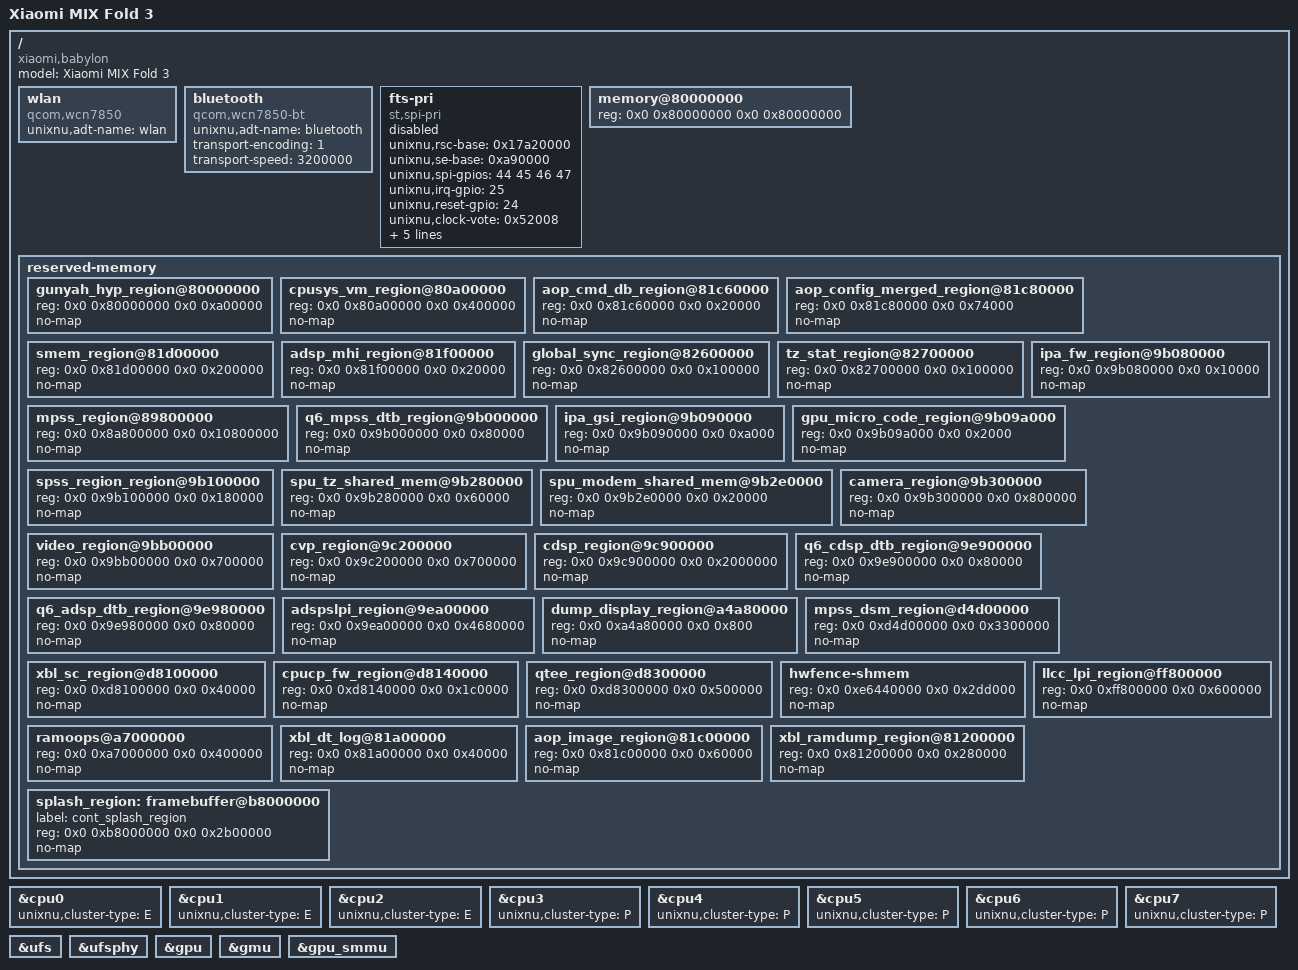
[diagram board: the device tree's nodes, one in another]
/dts-v1/;
/include/ "sm8550.dtsi"

// Generated from babylon live /sys/firmware/fdt (HyperOS 3.0.304.0, Android 16).
// Layout follows UniXNU-sheng dts/sheng.dts; reserved-memory follows UniXNU-zizhan gen_reserved.py approach.

/ {
    model = "Xiaomi MIX Fold 3";
    compatible = "xiaomi,babylon", "qcom,sm8550";

    wlan {
        compatible = "qcom,wcn7850";
        unixnu,adt-name = "wlan";
        status = "okay";
    };

    bluetooth {
        device_type = "bluetooth";
        compatible = "qcom,wcn7850-bt";
        unixnu,adt-name = "bluetooth";
        transport-encoding = <1>;
        transport-speed = <3200000>;
        status = "okay";
    };

    /* ST FingerTip FST2 (st,spi-pri of the stock dtbo fragment@36) on QUP1 SE4.
     *
     * The node is a REQUEST MARKER, not an export. It is deliberately status = "disabled":
     * devicetree.py exports a hardware node only when it carries unixnu,adt-name AND enabled(),
     * and arm_io_window() would then fold reg=0xa90000 into the arm-io base. That base must be
     * 16 MiB aligned and non-zero, so an SE below it would either fail the build ("an exported
     * register lies below 16 MiB") or move the SoC base the kernel reads. Nothing here is
     * exported, so the ADT is byte-for-byte what it was.
     *
     * pong_fts.c is NOT used: it is not in this repository and needs sys/pong_input.h and
     * pong_touch_post(), which exist only in zizhan's Pong input stack. The driver is the FTS
     * stage 1-3 path in package/TouchProbe.cpp, driven by its own FTS_* constants in
     * package/TouchBoard.h (TouchBoard.h is a header, not hardware, so it does not need this
     * node). Every register, pin, clock and rail value is written there, past devicetree.py's
     * hardware_properties() whitelist.
     *
     * Values below are the stock dtbo/baseline-DTB facts, kept with the node as the record. */
    fts-pri {
        compatible = "st,spi-pri";
        status = "disabled";
        /* apps_rsc@17a00000 drv@2 base (the drv-2 reg entry is 0x17a20000), where
         * AudioProbe::micRail() already sends its LDO votes. */
        unixnu,rsc-base = <0x17a20000>;
        /* vboot baseline DTB: /soc/qcom,qupv3_1_geni_se@ac0000/spi@a90000 reg 0xa90000 size 0x4000 */
        unixnu,se-base = <0xa90000>;
        /* qupv3_se4_spi_miso/mosi/clk/cs_active: gpio44/45/46 -> qup1_se4_l0/l1/l2, cs gpio47 */
        unixnu,spi-gpios = <44 45 46 47>;
        unixnu,irq-gpio = <25>;
        unixnu,reset-gpio = <24>;
        unixnu,clock-vote = <0x52008>;
        unixnu,clock-rcg = <0x184f0>;
        /* dvdd-supply -> L12B (pm_humu_l12, 1.8 V), avdd-supply -> L16B (pm_humu_l16, 2.8 V).
         * 2.8 V is the regulator's max: 3.3 V would be out of range. */
        unixnu,supply = "ldob12", "ldob16";
        unixnu,voltage-uv = <1800000 2800000>;
        unixnu,spi-hz = <4000000>;
        unixnu,chip-id = <0x3652>;
    };

    memory@80000000 {
        device_type = "memory";
        /* The low bank the ADT describes. This pair is not what bounds the loader's exclusion
         * walk: DarwinBoot reads darwinboot-memory-size (payload.adt owned_memory_size) for the
         * window and scans the UEFI map inside it, never dram-size. So enlarging this value
         * cannot make DarwinWindowExclusions find ranges, and the sibling window.holes are
         * carried by darwinboot-memory-excluded alone. Keep it equal to board.toml dram_size:
         * devicetree.py refuses the build when the two differ.
         *
         * Writing a size that does not fit one cell is a trap: the root node is
         * #size-cells = <2>, so a range is four cells, and 0x400000000 written as a single
         * cell is truncated by dtc to 0x0. The DTS then declares zero-length DRAM while
         * board.toml still says 16 GiB, and the build dies in packaging on
         * "payload.dram_size differs from the hardware DTS". */
        reg = <0x0 0x80000000 0x0 0x80000000>;
    };

    reserved-memory {
        #address-cells = <2>;
        #size-cells = <2>;
        ranges;
        gunyah_hyp_region@80000000 {
            reg = <0x0 0x80000000 0x0 0xa00000>;
            no-map;
        };
        cpusys_vm_region@80a00000 {
            reg = <0x0 0x80a00000 0x0 0x400000>;
            no-map;
        };
        aop_cmd_db_region@81c60000 {
            reg = <0x0 0x81c60000 0x0 0x20000>;
            no-map;
        };
        aop_config_merged_region@81c80000 {
            reg = <0x0 0x81c80000 0x0 0x74000>;
            no-map;
        };
        smem_region@81d00000 {
            reg = <0x0 0x81d00000 0x0 0x200000>;
            no-map;
        };
        adsp_mhi_region@81f00000 {
            reg = <0x0 0x81f00000 0x0 0x20000>;
            no-map;
        };
        global_sync_region@82600000 {
            reg = <0x0 0x82600000 0x0 0x100000>;
            no-map;
        };
        tz_stat_region@82700000 {
            reg = <0x0 0x82700000 0x0 0x100000>;
            no-map;
        };
        mpss_region@89800000 {
            reg = <0x0 0x8a800000 0x0 0x10800000>;
            no-map;
        };
        q6_mpss_dtb_region@9b000000 {
            reg = <0x0 0x9b000000 0x0 0x80000>;
            no-map;
        };
        ipa_fw_region@9b080000 {
            reg = <0x0 0x9b080000 0x0 0x10000>;
            no-map;
        };
        ipa_gsi_region@9b090000 {
            reg = <0x0 0x9b090000 0x0 0xa000>;
            no-map;
        };
        gpu_micro_code_region@9b09a000 {
            reg = <0x0 0x9b09a000 0x0 0x2000>;
            no-map;
        };
        spss_region_region@9b100000 {
            reg = <0x0 0x9b100000 0x0 0x180000>;
            no-map;
        };
        spu_tz_shared_mem@9b280000 {
            reg = <0x0 0x9b280000 0x0 0x60000>;
            no-map;
        };
        spu_modem_shared_mem@9b2e0000 {
            reg = <0x0 0x9b2e0000 0x0 0x20000>;
            no-map;
        };
        camera_region@9b300000 {
            reg = <0x0 0x9b300000 0x0 0x800000>;
            no-map;
        };
        video_region@9bb00000 {
            reg = <0x0 0x9bb00000 0x0 0x700000>;
            no-map;
        };
        cvp_region@9c200000 {
            reg = <0x0 0x9c200000 0x0 0x700000>;
            no-map;
        };
        cdsp_region@9c900000 {
            reg = <0x0 0x9c900000 0x0 0x2000000>;
            no-map;
        };
        q6_cdsp_dtb_region@9e900000 {
            reg = <0x0 0x9e900000 0x0 0x80000>;
            no-map;
        };
        q6_adsp_dtb_region@9e980000 {
            reg = <0x0 0x9e980000 0x0 0x80000>;
            no-map;
        };
        adspslpi_region@9ea00000 {
            reg = <0x0 0x9ea00000 0x0 0x4680000>;
            no-map;
        };
        dump_display_region@a4a80000 {
            reg = <0x0 0xa4a80000 0x0 0x800>;
            no-map;
        };
        mpss_dsm_region@d4d00000 {
            reg = <0x0 0xd4d00000 0x0 0x3300000>;
            no-map;
        };
        xbl_sc_region@d8100000 {
            reg = <0x0 0xd8100000 0x0 0x40000>;
            no-map;
        };
        cpucp_fw_region@d8140000 {
            reg = <0x0 0xd8140000 0x0 0x1c0000>;
            no-map;
        };
        qtee_region@d8300000 {
            reg = <0x0 0xd8300000 0x0 0x500000>;
            no-map;
        };
        hwfence-shmem {
            reg = <0x0 0xe6440000 0x0 0x2dd000>;
            no-map;
        };
        llcc_lpi_region@ff800000 {
            reg = <0x0 0xff800000 0x0 0x600000>;
            no-map;
        };
        ramoops@a7000000 {
            reg = <0x0 0xa7000000 0x0 0x400000>;
            no-map;
        };
        xbl_dt_log@81a00000 {
            reg = <0x0 0x81a00000 0x0 0x40000>;
            no-map;
        };
        aop_image_region@81c00000 {
            reg = <0x0 0x81c00000 0x0 0x60000>;
            no-map;
        };
        xbl_ramdump_region@81200000 {
            reg = <0x0 0x81200000 0x0 0x280000>;
            no-map;
        };
        splash_region: framebuffer@b8000000 {
            label = "cont_splash_region";
            reg = <0x0 0xb8000000 0x0 0x2b00000>;
            no-map;
        };
    };
};

// The scheduler runs the A510 cores as an E cluster and the others as a P cluster.
&cpu0 { unixnu,cluster-type = "E"; };
&cpu1 { unixnu,cluster-type = "E"; };
&cpu2 { unixnu,cluster-type = "E"; };
&cpu3 { unixnu,cluster-type = "P"; };
&cpu4 { unixnu,cluster-type = "P"; };
&cpu5 { unixnu,cluster-type = "P"; };
&cpu6 { unixnu,cluster-type = "P"; };
&cpu7 { unixnu,cluster-type = "P"; };
&ufs { status = "okay"; };
&ufsphy { status = "okay"; };
&gpu { status = "okay"; };
&gmu { status = "okay"; };
&gpu_smmu { status = "okay"; };
